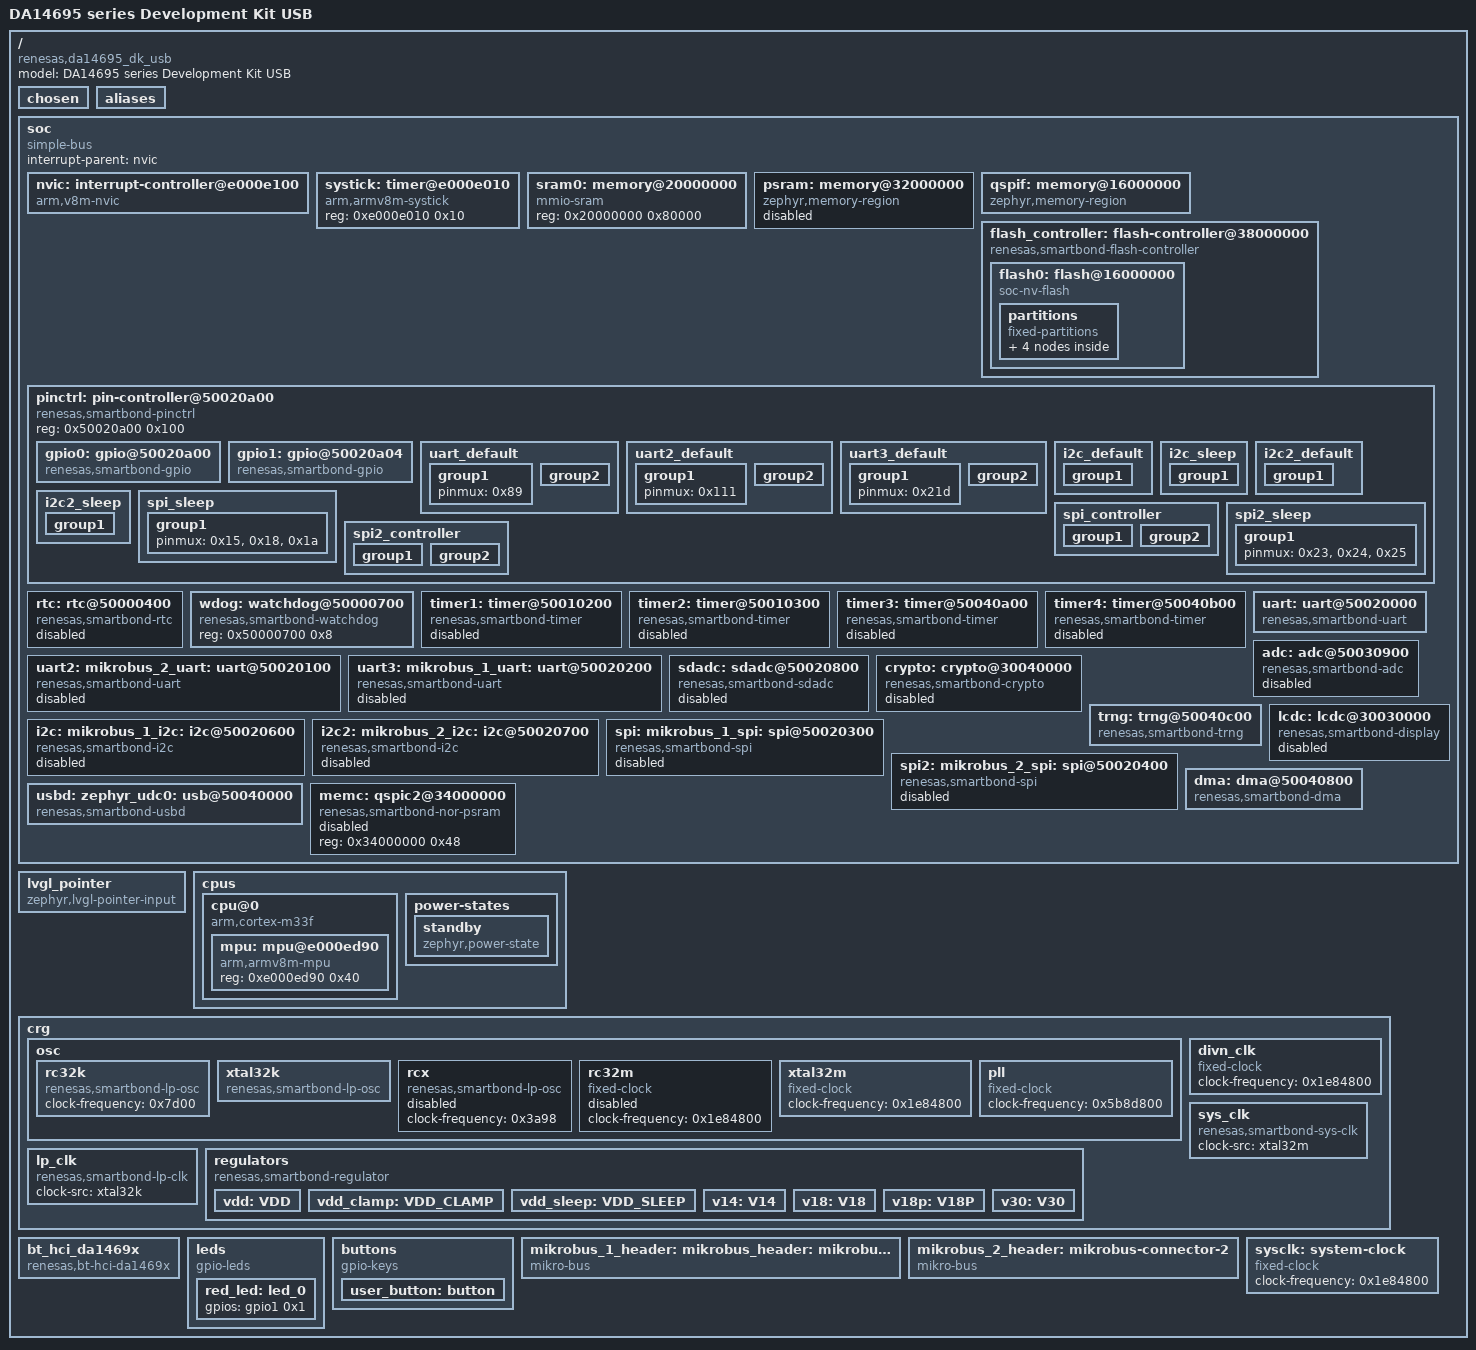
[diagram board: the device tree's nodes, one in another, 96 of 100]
/dts-v1/;

/* node '/' defined in zephyr/dts/common/skeleton.dtsi:9 */
/ {
	model = "DA14695 series Development Kit USB"; /* in zephyr/boards/renesas/da14695_dk_usb/da14695_dk_usb.dts:12 */
	compatible = "renesas,da14695_dk_usb";        /* in zephyr/boards/renesas/da14695_dk_usb/da14695_dk_usb.dts:13 */
	#address-cells = < 0x1 >;                     /* in zephyr/boards/renesas/da14695_dk_usb/da14695_dk_usb.dts:14 */
	#size-cells = < 0x1 >;                        /* in zephyr/boards/renesas/da14695_dk_usb/da14695_dk_usb.dts:15 */

	/* node '/chosen' defined in zephyr/dts/common/skeleton.dtsi:13 */
	chosen {
		zephyr,entropy = &trng;                      /* in zephyr/dts/arm/renesas/smartbond/da1469x.dtsi:16 */
		zephyr,flash-controller = &flash_controller; /* in zephyr/dts/arm/renesas/smartbond/da1469x.dtsi:17 */
		zephyr,sram = &sram0;                        /* in zephyr/boards/renesas/da14695_dk_usb/da14695_dk_usb.dts:18 */
		zephyr,flash = &flash0;                      /* in zephyr/boards/renesas/da14695_dk_usb/da14695_dk_usb.dts:19 */
		zephyr,console = &uart;                      /* in zephyr/boards/renesas/da14695_dk_usb/da14695_dk_usb.dts:20 */
		zephyr,shell-uart = &uart;                   /* in zephyr/boards/renesas/da14695_dk_usb/da14695_dk_usb.dts:21 */
		zephyr,code-partition = &slot0_partition;    /* in zephyr/boards/renesas/da14695_dk_usb/da14695_dk_usb.dts:22 */
		zephyr,bt-hci = &bt_hci_da1469x;             /* in zephyr/boards/renesas/da14695_dk_usb/da14695_dk_usb.dts:23 */
	};

	/* node '/aliases' defined in zephyr/dts/common/skeleton.dtsi:15 */
	aliases {
		led0 = &red_led;    /* in zephyr/boards/renesas/da14695_dk_usb/da14695_dk_usb.dts:91 */
		watchdog0 = &wdog;  /* in zephyr/boards/renesas/da14695_dk_usb/da14695_dk_usb.dts:92 */
		sw0 = &user_button; /* in zephyr/boards/renesas/da14695_dk_usb/da14695_dk_usb.dts:93 */
		rtc = &rtc;         /* in zephyr/boards/renesas/da14695_dk_usb/da14695_dk_usb.dts:94 */
	};

	/* node '/soc' defined in zephyr/dts/arm/armv8-m.dtsi:6 */
	soc {
		#address-cells = < 0x1 >;     /* in zephyr/dts/arm/armv8-m.dtsi:7 */
		#size-cells = < 0x1 >;        /* in zephyr/dts/arm/armv8-m.dtsi:8 */
		compatible = "simple-bus";    /* in zephyr/dts/arm/armv8-m.dtsi:9 */
		interrupt-parent = < &nvic >; /* in zephyr/dts/arm/armv8-m.dtsi:10 */
		ranges;                       /* in zephyr/dts/arm/armv8-m.dtsi:11 */

		/* node '/soc/interrupt-controller@e000e100' defined in zephyr/dts/arm/armv8-m.dtsi:13 */
		nvic: interrupt-controller@e000e100 {
			#address-cells = < 0x1 >;            /* in zephyr/dts/arm/armv8-m.dtsi:14 */
			compatible = "arm,v8m-nvic";         /* in zephyr/dts/arm/armv8-m.dtsi:15 */
			reg = < 0xe000e100 0xc00 >;          /* in zephyr/dts/arm/armv8-m.dtsi:16 */
			interrupt-controller;                /* in zephyr/dts/arm/armv8-m.dtsi:17 */
			#interrupt-cells = < 0x2 >;          /* in zephyr/dts/arm/armv8-m.dtsi:18 */
			arm,num-irq-priority-bits = < 0x4 >; /* in zephyr/dts/arm/renesas/smartbond/da1469x.dtsi:437 */
			phandle = < 0x1 >;                   /* in zephyr/dts/arm/armv8-m.dtsi:10 */
		};

		/* node '/soc/timer@e000e010' defined in zephyr/dts/arm/armv8-m.dtsi:21 */
		systick: timer@e000e010 {
			compatible = "arm,armv8m-systick"; /* in zephyr/dts/arm/armv8-m.dtsi:22 */
			reg = < 0xe000e010 0x10 >;         /* in zephyr/dts/arm/armv8-m.dtsi:23 */
		};

		/* node '/soc/memory@20000000' defined in zephyr/dts/arm/renesas/smartbond/da1469x.dtsi:174 */
		sram0: memory@20000000 {
			compatible = "mmio-sram";     /* in zephyr/dts/arm/renesas/smartbond/da1469x.dtsi:175 */
			reg = < 0x20000000 0x80000 >; /* in zephyr/dts/arm/renesas/smartbond/da14695.dtsi:7 */
		};

		/* node '/soc/memory@32000000' defined in zephyr/dts/arm/renesas/smartbond/da1469x.dtsi:178 */
		psram: memory@32000000 {
			compatible = "zephyr,memory-region"; /* in zephyr/dts/arm/renesas/smartbond/da1469x.dtsi:179 */
			device_type = "memory";              /* in zephyr/dts/arm/renesas/smartbond/da1469x.dtsi:180 */
			reg = < 0x32000000 0x2000000 >;      /* in zephyr/dts/arm/renesas/smartbond/da1469x.dtsi:181 */
			zephyr,memory-region = "PSRAM";      /* in zephyr/dts/arm/renesas/smartbond/da1469x.dtsi:182 */
			status = "disabled";                 /* in zephyr/dts/arm/renesas/smartbond/da1469x.dtsi:183 */
		};

		/* node '/soc/memory@16000000' defined in zephyr/dts/arm/renesas/smartbond/da1469x.dtsi:186 */
		qspif: memory@16000000 {
			compatible = "zephyr,memory-region"; /* in zephyr/dts/arm/renesas/smartbond/da1469x.dtsi:187 */
			reg = < 0x16000000 0x2000000 >;      /* in zephyr/dts/arm/renesas/smartbond/da1469x.dtsi:188 */
			zephyr,memory-region = "QSPIF";      /* in zephyr/dts/arm/renesas/smartbond/da1469x.dtsi:189 */
		};

		/* node '/soc/flash-controller@38000000' defined in zephyr/dts/arm/renesas/smartbond/da1469x.dtsi:192 */
		flash_controller: flash-controller@38000000 {
			compatible = "renesas,smartbond-flash-controller"; /* in zephyr/dts/arm/renesas/smartbond/da1469x.dtsi:193 */
			reg = < 0x38000000 0xb0 >;                         /* in zephyr/dts/arm/renesas/smartbond/da1469x.dtsi:194 */
			#address-cells = < 0x1 >;                          /* in zephyr/dts/arm/renesas/smartbond/da1469x.dtsi:196 */
			#size-cells = < 0x1 >;                             /* in zephyr/dts/arm/renesas/smartbond/da1469x.dtsi:197 */
			read-cs-idle-delay = < 0x32 >;                     /* in zephyr/dts/arm/renesas/smartbond/da1469x.dtsi:199 */
			erase-cs-idle-delay = < 0x32 >;                    /* in zephyr/dts/arm/renesas/smartbond/da1469x.dtsi:200 */

			/* node '/soc/flash-controller@38000000/flash@16000000' defined in zephyr/dts/arm/renesas/smartbond/da1469x.dtsi:202 */
			flash0: flash@16000000 {
				compatible = "soc-nv-flash";   /* in zephyr/dts/arm/renesas/smartbond/da1469x.dtsi:203 */
				erase-block-size = < 0x1000 >; /* in zephyr/dts/arm/renesas/smartbond/da1469x.dtsi:204 */
				write-block-size = < 0x1 >;    /* in zephyr/dts/arm/renesas/smartbond/da1469x.dtsi:205 */
				reg = < 0x16000000 0x400000 >; /* in zephyr/boards/renesas/da14695_dk_usb/da14695_dk_usb.dts:105 */

				/* node '/soc/flash-controller@38000000/flash@16000000/partitions' defined in zephyr/boards/renesas/da14695_dk_usb/da14695_dk_usb.dts:107 */
				partitions {
					compatible = "fixed-partitions"; /* in zephyr/boards/renesas/da14695_dk_usb/da14695_dk_usb.dts:108 */
					#address-cells = < 0x1 >;        /* in zephyr/boards/renesas/da14695_dk_usb/da14695_dk_usb.dts:109 */
					#size-cells = < 0x1 >;           /* in zephyr/boards/renesas/da14695_dk_usb/da14695_dk_usb.dts:110 */

					/* node '/soc/flash-controller@38000000/flash@16000000/partitions/partition@2400' defined in zephyr/boards/renesas/da14695_dk_usb/da14695_dk_usb.dts:125 */
					boot_partition: partition@2400 {
						label = "mcuboot";       /* in zephyr/boards/renesas/da14695_dk_usb/da14695_dk_usb.dts:126 */
						reg = < 0x2400 0xdc00 >; /* in zephyr/boards/renesas/da14695_dk_usb/da14695_dk_usb.dts:127 */
					};

					/* node '/soc/flash-controller@38000000/flash@16000000/partitions/partition@10000' defined in zephyr/boards/renesas/da14695_dk_usb/da14695_dk_usb.dts:129 */
					slot0_partition: partition@10000 {
						label = "image-0";         /* in zephyr/boards/renesas/da14695_dk_usb/da14695_dk_usb.dts:130 */
						reg = < 0x10000 0x80000 >; /* in zephyr/boards/renesas/da14695_dk_usb/da14695_dk_usb.dts:131 */
					};

					/* node '/soc/flash-controller@38000000/flash@16000000/partitions/partition@90000' defined in zephyr/boards/renesas/da14695_dk_usb/da14695_dk_usb.dts:133 */
					slot1_partition: partition@90000 {
						label = "image-1";         /* in zephyr/boards/renesas/da14695_dk_usb/da14695_dk_usb.dts:134 */
						reg = < 0x90000 0x80000 >; /* in zephyr/boards/renesas/da14695_dk_usb/da14695_dk_usb.dts:135 */
					};

					/* node '/soc/flash-controller@38000000/flash@16000000/partitions/partition@110000' defined in zephyr/boards/renesas/da14695_dk_usb/da14695_dk_usb.dts:137 */
					storage_partition: partition@110000 {
						label = "storage";         /* in zephyr/boards/renesas/da14695_dk_usb/da14695_dk_usb.dts:138 */
						reg = < 0x110000 0x8000 >; /* in zephyr/boards/renesas/da14695_dk_usb/da14695_dk_usb.dts:139 */
					};
				};
			};
		};

		/* node '/soc/pin-controller@50020a00' defined in zephyr/dts/arm/renesas/smartbond/da1469x.dtsi:209 */
		pinctrl: pin-controller@50020a00 {
			compatible = "renesas,smartbond-pinctrl"; /* in zephyr/dts/arm/renesas/smartbond/da1469x.dtsi:210 */
			reg = < 0x50020a00 0x100 >;               /* in zephyr/dts/arm/renesas/smartbond/da1469x.dtsi:211 */
			#address-cells = < 0x1 >;                 /* in zephyr/dts/arm/renesas/smartbond/da1469x.dtsi:212 */
			#size-cells = < 0x1 >;                    /* in zephyr/dts/arm/renesas/smartbond/da1469x.dtsi:213 */

			/* node '/soc/pin-controller@50020a00/gpio@50020a00' defined in zephyr/dts/arm/renesas/smartbond/da1469x.dtsi:215 */
			gpio0: gpio@50020a00 {
				compatible = "renesas,smartbond-gpio";                                    /* in zephyr/dts/arm/renesas/smartbond/da1469x.dtsi:216 */
				gpio-controller;                                                          /* in zephyr/dts/arm/renesas/smartbond/da1469x.dtsi:217 */
				#gpio-cells = < 0x2 >;                                                    /* in zephyr/dts/arm/renesas/smartbond/da1469x.dtsi:218 */
				port = < 0x0 >;                                                           /* in zephyr/dts/arm/renesas/smartbond/da1469x.dtsi:219 */
				ngpios = < 0x20 >;                                                        /* in zephyr/dts/arm/renesas/smartbond/da1469x.dtsi:220 */
				reg = < 0x50020a00 0x14 0x50020a18 0x80 0x50000070 0xc 0x50000114 0x24 >; /* in zephyr/dts/arm/renesas/smartbond/da1469x.dtsi:221 */
				reg-names = "data",
				            "mode",
				            "latch",
				            "wkup";                                                       /* in zephyr/dts/arm/renesas/smartbond/da1469x.dtsi:225 */
				interrupts = < 0x26 0x0 >;                                                /* in zephyr/dts/arm/renesas/smartbond/da1469x.dtsi:226 */
				status = "okay";                                                          /* in zephyr/boards/renesas/da14695_dk_usb/da14695_dk_usb.dts:145 */
				phandle = < 0x14 >;                                                       /* in zephyr/boards/renesas/da14695_dk_usb/da14695_dk_usb.dts:38 */
			};

			/* node '/soc/pin-controller@50020a00/gpio@50020a04' defined in zephyr/dts/arm/renesas/smartbond/da1469x.dtsi:229 */
			gpio1: gpio@50020a04 {
				compatible = "renesas,smartbond-gpio";                                    /* in zephyr/dts/arm/renesas/smartbond/da1469x.dtsi:230 */
				gpio-controller;                                                          /* in zephyr/dts/arm/renesas/smartbond/da1469x.dtsi:231 */
				#gpio-cells = < 0x2 >;                                                    /* in zephyr/dts/arm/renesas/smartbond/da1469x.dtsi:232 */
				port = < 0x1 >;                                                           /* in zephyr/dts/arm/renesas/smartbond/da1469x.dtsi:233 */
				reg = < 0x50020a04 0x14 0x50020a98 0x5c 0x5000007c 0xc 0x50000118 0x24 >; /* in zephyr/dts/arm/renesas/smartbond/da1469x.dtsi:235 */
				reg-names = "data",
				            "mode",
				            "latch",
				            "wkup";                                                       /* in zephyr/dts/arm/renesas/smartbond/da1469x.dtsi:239 */
				interrupts = < 0x27 0x0 >;                                                /* in zephyr/dts/arm/renesas/smartbond/da1469x.dtsi:240 */
				ngpios = < 0xc >;                                                         /* in zephyr/dts/arm/renesas/smartbond/da14695.dtsi:11 */
				status = "okay";                                                          /* in zephyr/boards/renesas/da14695_dk_usb/da14695_dk_usb.dts:149 */
				phandle = < 0x13 >;                                                       /* in zephyr/boards/renesas/da14695_dk_usb/da14695_dk_usb.dts:30 */
			};

			/* node '/soc/pin-controller@50020a00/uart_default' defined in zephyr/boards/renesas/da14695_dk_usb/da14695_dk_usb-pinctrl.dtsi:9 */
			uart_default: uart_default {
				phandle = < 0x4 >; /* in zephyr/boards/renesas/da14695_dk_usb/da14695_dk_usb.dts:155 */

				/* node '/soc/pin-controller@50020a00/uart_default/group1' defined in zephyr/boards/renesas/da14695_dk_usb/da14695_dk_usb-pinctrl.dtsi:10 */
				group1 {
					pinmux = < 0x89 >; /* in zephyr/boards/renesas/da14695_dk_usb/da14695_dk_usb-pinctrl.dtsi:11 */
				};

				/* node '/soc/pin-controller@50020a00/uart_default/group2' defined in zephyr/boards/renesas/da14695_dk_usb/da14695_dk_usb-pinctrl.dtsi:14 */
				group2 {
					pinmux = < 0x48 >; /* in zephyr/boards/renesas/da14695_dk_usb/da14695_dk_usb-pinctrl.dtsi:15 */
					bias-pull-up;      /* in zephyr/boards/renesas/da14695_dk_usb/da14695_dk_usb-pinctrl.dtsi:16 */
				};
			};

			/* node '/soc/pin-controller@50020a00/uart2_default' defined in zephyr/boards/renesas/da14695_dk_usb/da14695_dk_usb-pinctrl.dtsi:20 */
			uart2_default: uart2_default {
				phandle = < 0x5 >; /* in zephyr/boards/renesas/da14695_dk_usb/da14695_dk_usb.dts:161 */

				/* node '/soc/pin-controller@50020a00/uart2_default/group1' defined in zephyr/boards/renesas/da14695_dk_usb/da14695_dk_usb-pinctrl.dtsi:21 */
				group1 {
					pinmux = < 0x111 >; /* in zephyr/boards/renesas/da14695_dk_usb/da14695_dk_usb-pinctrl.dtsi:22 */
				};

				/* node '/soc/pin-controller@50020a00/uart2_default/group2' defined in zephyr/boards/renesas/da14695_dk_usb/da14695_dk_usb-pinctrl.dtsi:25 */
				group2 {
					pinmux = < 0xe8 >; /* in zephyr/boards/renesas/da14695_dk_usb/da14695_dk_usb-pinctrl.dtsi:26 */
					bias-pull-up;      /* in zephyr/boards/renesas/da14695_dk_usb/da14695_dk_usb-pinctrl.dtsi:27 */
				};
			};

			/* node '/soc/pin-controller@50020a00/uart3_default' defined in zephyr/boards/renesas/da14695_dk_usb/da14695_dk_usb-pinctrl.dtsi:31 */
			uart3_default: uart3_default {
				phandle = < 0x6 >; /* in zephyr/boards/renesas/da14695_dk_usb/da14695_dk_usb.dts:167 */

				/* node '/soc/pin-controller@50020a00/uart3_default/group1' defined in zephyr/boards/renesas/da14695_dk_usb/da14695_dk_usb-pinctrl.dtsi:32 */
				group1 {
					pinmux = < 0x21d >; /* in zephyr/boards/renesas/da14695_dk_usb/da14695_dk_usb-pinctrl.dtsi:33 */
				};

				/* node '/soc/pin-controller@50020a00/uart3_default/group2' defined in zephyr/boards/renesas/da14695_dk_usb/da14695_dk_usb-pinctrl.dtsi:36 */
				group2 {
					pinmux = < 0x1dc >; /* in zephyr/boards/renesas/da14695_dk_usb/da14695_dk_usb-pinctrl.dtsi:37 */
					bias-pull-up;       /* in zephyr/boards/renesas/da14695_dk_usb/da14695_dk_usb-pinctrl.dtsi:38 */
				};
			};

			/* node '/soc/pin-controller@50020a00/i2c_default' defined in zephyr/boards/renesas/da14695_dk_usb/da14695_dk_usb-pinctrl.dtsi:42 */
			i2c_default: i2c_default {
				phandle = < 0x7 >; /* in zephyr/boards/renesas/da14695_dk_usb/da14695_dk_usb.dts:209 */

				/* node '/soc/pin-controller@50020a00/i2c_default/group1' defined in zephyr/boards/renesas/da14695_dk_usb/da14695_dk_usb-pinctrl.dtsi:43 */
				group1 {
					pinmux = < 0x59f >,
					         < 0x55e >; /* in zephyr/boards/renesas/da14695_dk_usb/da14695_dk_usb-pinctrl.dtsi:44 */
					bias-pull-up;       /* in zephyr/boards/renesas/da14695_dk_usb/da14695_dk_usb-pinctrl.dtsi:46 */
				};
			};

			/* node '/soc/pin-controller@50020a00/i2c_sleep' defined in zephyr/boards/renesas/da14695_dk_usb/da14695_dk_usb-pinctrl.dtsi:50 */
			i2c_sleep: i2c_sleep {
				phandle = < 0x8 >; /* in zephyr/boards/renesas/da14695_dk_usb/da14695_dk_usb.dts:210 */

				/* node '/soc/pin-controller@50020a00/i2c_sleep/group1' defined in zephyr/boards/renesas/da14695_dk_usb/da14695_dk_usb-pinctrl.dtsi:51 */
				group1 {
					pinmux = < 0x1f >,
					         < 0x1e >; /* in zephyr/boards/renesas/da14695_dk_usb/da14695_dk_usb-pinctrl.dtsi:52 */
					bias-pull-up;      /* in zephyr/boards/renesas/da14695_dk_usb/da14695_dk_usb-pinctrl.dtsi:54 */
				};
			};

			/* node '/soc/pin-controller@50020a00/i2c2_default' defined in zephyr/boards/renesas/da14695_dk_usb/da14695_dk_usb-pinctrl.dtsi:58 */
			i2c2_default: i2c2_default {
				phandle = < 0x9 >; /* in zephyr/boards/renesas/da14695_dk_usb/da14695_dk_usb.dts:215 */

				/* node '/soc/pin-controller@50020a00/i2c2_default/group1' defined in zephyr/boards/renesas/da14695_dk_usb/da14695_dk_usb-pinctrl.dtsi:59 */
				group1 {
					pinmux = < 0x613 >,
					         < 0x5d2 >; /* in zephyr/boards/renesas/da14695_dk_usb/da14695_dk_usb-pinctrl.dtsi:60 */
					bias-pull-up;       /* in zephyr/boards/renesas/da14695_dk_usb/da14695_dk_usb-pinctrl.dtsi:62 */
				};
			};

			/* node '/soc/pin-controller@50020a00/i2c2_sleep' defined in zephyr/boards/renesas/da14695_dk_usb/da14695_dk_usb-pinctrl.dtsi:66 */
			i2c2_sleep: i2c2_sleep {
				phandle = < 0xa >; /* in zephyr/boards/renesas/da14695_dk_usb/da14695_dk_usb.dts:216 */

				/* node '/soc/pin-controller@50020a00/i2c2_sleep/group1' defined in zephyr/boards/renesas/da14695_dk_usb/da14695_dk_usb-pinctrl.dtsi:67 */
				group1 {
					pinmux = < 0x13 >,
					         < 0x12 >; /* in zephyr/boards/renesas/da14695_dk_usb/da14695_dk_usb-pinctrl.dtsi:68 */
					bias-pull-up;      /* in zephyr/boards/renesas/da14695_dk_usb/da14695_dk_usb-pinctrl.dtsi:70 */
				};
			};

			/* node '/soc/pin-controller@50020a00/spi_sleep' defined in zephyr/boards/renesas/da14695_dk_usb/da14695_dk_usb-pinctrl.dtsi:74 */
			spi_sleep: spi_sleep {
				phandle = < 0xc >; /* in zephyr/boards/renesas/da14695_dk_usb/da14695_dk_usb.dts:222 */

				/* node '/soc/pin-controller@50020a00/spi_sleep/group1' defined in zephyr/boards/renesas/da14695_dk_usb/da14695_dk_usb-pinctrl.dtsi:75 */
				group1 {
					pinmux = < 0x15 >,
					         < 0x18 >,
					         < 0x1a >; /* in zephyr/boards/renesas/da14695_dk_usb/da14695_dk_usb-pinctrl.dtsi:76 */
				};
			};

			/* node '/soc/pin-controller@50020a00/spi_controller' defined in zephyr/boards/renesas/da14695_dk_usb/da14695_dk_usb-pinctrl.dtsi:82 */
			spi_controller: spi_controller {
				phandle = < 0xb >; /* in zephyr/boards/renesas/da14695_dk_usb/da14695_dk_usb.dts:221 */

				/* node '/soc/pin-controller@50020a00/spi_controller/group1' defined in zephyr/boards/renesas/da14695_dk_usb/da14695_dk_usb-pinctrl.dtsi:83 */
				group1 {
					pinmux = < 0x3d5 >,
					         < 0x39a >; /* in zephyr/boards/renesas/da14695_dk_usb/da14695_dk_usb-pinctrl.dtsi:84 */
					output-enable;      /* in zephyr/boards/renesas/da14695_dk_usb/da14695_dk_usb-pinctrl.dtsi:86 */
				};

				/* node '/soc/pin-controller@50020a00/spi_controller/group2' defined in zephyr/boards/renesas/da14695_dk_usb/da14695_dk_usb-pinctrl.dtsi:89 */
				group2 {
					pinmux = < 0x358 >; /* in zephyr/boards/renesas/da14695_dk_usb/da14695_dk_usb-pinctrl.dtsi:90 */
					input-enable;       /* in zephyr/boards/renesas/da14695_dk_usb/da14695_dk_usb-pinctrl.dtsi:91 */
				};
			};

			/* node '/soc/pin-controller@50020a00/spi2_sleep' defined in zephyr/boards/renesas/da14695_dk_usb/da14695_dk_usb-pinctrl.dtsi:95 */
			spi2_sleep: spi2_sleep {
				phandle = < 0xe >; /* in zephyr/boards/renesas/da14695_dk_usb/da14695_dk_usb.dts:228 */

				/* node '/soc/pin-controller@50020a00/spi2_sleep/group1' defined in zephyr/boards/renesas/da14695_dk_usb/da14695_dk_usb-pinctrl.dtsi:96 */
				group1 {
					pinmux = < 0x23 >,
					         < 0x24 >,
					         < 0x25 >; /* in zephyr/boards/renesas/da14695_dk_usb/da14695_dk_usb-pinctrl.dtsi:97 */
				};
			};

			/* node '/soc/pin-controller@50020a00/spi2_controller' defined in zephyr/boards/renesas/da14695_dk_usb/da14695_dk_usb-pinctrl.dtsi:103 */
			spi2_controller: spi2_controller {
				phandle = < 0xd >; /* in zephyr/boards/renesas/da14695_dk_usb/da14695_dk_usb.dts:227 */

				/* node '/soc/pin-controller@50020a00/spi2_controller/group1' defined in zephyr/boards/renesas/da14695_dk_usb/da14695_dk_usb-pinctrl.dtsi:104 */
				group1 {
					pinmux = < 0x4e3 >,
					         < 0x4a5 >; /* in zephyr/boards/renesas/da14695_dk_usb/da14695_dk_usb-pinctrl.dtsi:105 */
					output-enable;      /* in zephyr/boards/renesas/da14695_dk_usb/da14695_dk_usb-pinctrl.dtsi:107 */
				};

				/* node '/soc/pin-controller@50020a00/spi2_controller/group2' defined in zephyr/boards/renesas/da14695_dk_usb/da14695_dk_usb-pinctrl.dtsi:110 */
				group2 {
					pinmux = < 0x464 >; /* in zephyr/boards/renesas/da14695_dk_usb/da14695_dk_usb-pinctrl.dtsi:111 */
					input-enable;       /* in zephyr/boards/renesas/da14695_dk_usb/da14695_dk_usb-pinctrl.dtsi:112 */
				};
			};
		};

		/* node '/soc/rtc@50000400' defined in zephyr/dts/arm/renesas/smartbond/da1469x.dtsi:244 */
		rtc: rtc@50000400 {
			compatible = "renesas,smartbond-rtc"; /* in zephyr/dts/arm/renesas/smartbond/da1469x.dtsi:245 */
			reg = < 0x50000400 0x98 >;            /* in zephyr/dts/arm/renesas/smartbond/da1469x.dtsi:246 */
			interrupts = < 0x12 0x0 >;            /* in zephyr/dts/arm/renesas/smartbond/da1469x.dtsi:247 */
			alarms-count = < 0x1 >;               /* in zephyr/dts/arm/renesas/smartbond/da1469x.dtsi:248 */
			status = "disabled";                  /* in zephyr/dts/arm/renesas/smartbond/da1469x.dtsi:249 */
		};

		/* node '/soc/watchdog@50000700' defined in zephyr/dts/arm/renesas/smartbond/da1469x.dtsi:252 */
		wdog: watchdog@50000700 {
			compatible = "renesas,smartbond-watchdog"; /* in zephyr/dts/arm/renesas/smartbond/da1469x.dtsi:253 */
			reg = < 0x50000700 0x8 >;                  /* in zephyr/dts/arm/renesas/smartbond/da1469x.dtsi:254 */
			status = "okay";                           /* in zephyr/dts/arm/renesas/smartbond/da1469x.dtsi:255 */
		};

		/* node '/soc/timer@50010200' defined in zephyr/dts/arm/renesas/smartbond/da1469x.dtsi:258 */
		timer1: timer@50010200 {
			compatible = "renesas,smartbond-timer"; /* in zephyr/dts/arm/renesas/smartbond/da1469x.dtsi:259 */
			reg = < 0x50010200 0x300 >;             /* in zephyr/dts/arm/renesas/smartbond/da1469x.dtsi:260 */
			clock-src = < &lp_clk >;                /* in zephyr/dts/arm/renesas/smartbond/da1469x.dtsi:261 */
			interrupts = < 0x10 0x0 >;              /* in zephyr/dts/arm/renesas/smartbond/da1469x.dtsi:262 */
			prescaler = < 0x1 >;                    /* in zephyr/dts/arm/renesas/smartbond/da1469x.dtsi:263 */
			status = "disabled";                    /* in zephyr/dts/arm/renesas/smartbond/da1469x.dtsi:264 */
		};

		/* node '/soc/timer@50010300' defined in zephyr/dts/arm/renesas/smartbond/da1469x.dtsi:267 */
		timer2: timer@50010300 {
			compatible = "renesas,smartbond-timer"; /* in zephyr/dts/arm/renesas/smartbond/da1469x.dtsi:268 */
			reg = < 0x50010300 0x300 >;             /* in zephyr/dts/arm/renesas/smartbond/da1469x.dtsi:269 */
			clock-src = < &divn_clk >;              /* in zephyr/dts/arm/renesas/smartbond/da1469x.dtsi:270 */
			interrupts = < 0x11 0x0 >;              /* in zephyr/dts/arm/renesas/smartbond/da1469x.dtsi:271 */
			prescaler = < 0x20 >;                   /* in zephyr/dts/arm/renesas/smartbond/da1469x.dtsi:272 */
			status = "reserved";                    /* in zephyr/dts/arm/renesas/smartbond/da1469x.dtsi:273 */
		};

		/* node '/soc/timer@50040a00' defined in zephyr/dts/arm/renesas/smartbond/da1469x.dtsi:276 */
		timer3: timer@50040a00 {
			compatible = "renesas,smartbond-timer"; /* in zephyr/dts/arm/renesas/smartbond/da1469x.dtsi:277 */
			reg = < 0x50040a00 0x300 >;             /* in zephyr/dts/arm/renesas/smartbond/da1469x.dtsi:278 */
			clock-src = < &lp_clk >;                /* in zephyr/dts/arm/renesas/smartbond/da1469x.dtsi:279 */
			interrupts = < 0x22 0x0 >;              /* in zephyr/dts/arm/renesas/smartbond/da1469x.dtsi:280 */
			prescaler = < 0x1f >;                   /* in zephyr/dts/arm/renesas/smartbond/da1469x.dtsi:281 */
			status = "disabled";                    /* in zephyr/dts/arm/renesas/smartbond/da1469x.dtsi:282 */
		};

		/* node '/soc/timer@50040b00' defined in zephyr/dts/arm/renesas/smartbond/da1469x.dtsi:285 */
		timer4: timer@50040b00 {
			compatible = "renesas,smartbond-timer"; /* in zephyr/dts/arm/renesas/smartbond/da1469x.dtsi:286 */
			reg = < 0x50040b00 0x300 >;             /* in zephyr/dts/arm/renesas/smartbond/da1469x.dtsi:287 */
			clock-src = < &divn_clk >;              /* in zephyr/dts/arm/renesas/smartbond/da1469x.dtsi:288 */
			interrupts = < 0x23 0x0 >;              /* in zephyr/dts/arm/renesas/smartbond/da1469x.dtsi:289 */
			prescaler = < 0x20 >;                   /* in zephyr/dts/arm/renesas/smartbond/da1469x.dtsi:290 */
			status = "disabled";                    /* in zephyr/dts/arm/renesas/smartbond/da1469x.dtsi:291 */
		};

		/* node '/soc/uart@50020000' defined in zephyr/dts/arm/renesas/smartbond/da1469x.dtsi:294 */
		uart: uart@50020000 {
			compatible = "renesas,smartbond-uart"; /* in zephyr/dts/arm/renesas/smartbond/da1469x.dtsi:295 */
			reg = < 0x50020000 0x100 >;            /* in zephyr/dts/arm/renesas/smartbond/da1469x.dtsi:296 */
			periph-clock-config = < 0x1 >;         /* in zephyr/dts/arm/renesas/smartbond/da1469x.dtsi:297 */
			interrupts = < 0x5 0x0 >;              /* in zephyr/dts/arm/renesas/smartbond/da1469x.dtsi:298 */
			current-speed = < 0x1c200 >;           /* in zephyr/boards/renesas/da14695_dk_usb/da14695_dk_usb.dts:153 */
			status = "okay";                       /* in zephyr/boards/renesas/da14695_dk_usb/da14695_dk_usb.dts:154 */
			pinctrl-0 = < &uart_default >;         /* in zephyr/boards/renesas/da14695_dk_usb/da14695_dk_usb.dts:155 */
			pinctrl-names = "default";             /* in zephyr/boards/renesas/da14695_dk_usb/da14695_dk_usb.dts:156 */
		};

		/* node '/soc/uart@50020100' defined in zephyr/dts/arm/renesas/smartbond/da1469x.dtsi:302 */
		uart2: mikrobus_2_uart: uart@50020100 {
			compatible = "renesas,smartbond-uart"; /* in zephyr/dts/arm/renesas/smartbond/da1469x.dtsi:303 */
			reg = < 0x50020100 0x100 >;            /* in zephyr/dts/arm/renesas/smartbond/da1469x.dtsi:304 */
			periph-clock-config = < 0x2 >;         /* in zephyr/dts/arm/renesas/smartbond/da1469x.dtsi:305 */
			interrupts = < 0x6 0x0 >;              /* in zephyr/dts/arm/renesas/smartbond/da1469x.dtsi:306 */
			hw-flow-control-supported;             /* in zephyr/dts/arm/renesas/smartbond/da1469x.dtsi:307 */
			status = "disabled";                   /* in zephyr/dts/arm/renesas/smartbond/da1469x.dtsi:308 */
			current-speed = < 0x1c200 >;           /* in zephyr/boards/renesas/da14695_dk_usb/da14695_dk_usb.dts:160 */
			pinctrl-0 = < &uart2_default >;        /* in zephyr/boards/renesas/da14695_dk_usb/da14695_dk_usb.dts:161 */
			pinctrl-names = "default";             /* in zephyr/boards/renesas/da14695_dk_usb/da14695_dk_usb.dts:162 */
		};

		/* node '/soc/uart@50020200' defined in zephyr/dts/arm/renesas/smartbond/da1469x.dtsi:311 */
		uart3: mikrobus_1_uart: mikrobus_serial: uart@50020200 {
			compatible = "renesas,smartbond-uart"; /* in zephyr/dts/arm/renesas/smartbond/da1469x.dtsi:312 */
			reg = < 0x50020200 0x100 >;            /* in zephyr/dts/arm/renesas/smartbond/da1469x.dtsi:313 */
			periph-clock-config = < 0x8 >;         /* in zephyr/dts/arm/renesas/smartbond/da1469x.dtsi:314 */
			interrupts = < 0x7 0x0 >;              /* in zephyr/dts/arm/renesas/smartbond/da1469x.dtsi:315 */
			hw-flow-control-supported;             /* in zephyr/dts/arm/renesas/smartbond/da1469x.dtsi:316 */
			status = "disabled";                   /* in zephyr/dts/arm/renesas/smartbond/da1469x.dtsi:317 */
			current-speed = < 0x1c200 >;           /* in zephyr/boards/renesas/da14695_dk_usb/da14695_dk_usb.dts:166 */
			pinctrl-0 = < &uart3_default >;        /* in zephyr/boards/renesas/da14695_dk_usb/da14695_dk_usb.dts:167 */
			pinctrl-names = "default";             /* in zephyr/boards/renesas/da14695_dk_usb/da14695_dk_usb.dts:168 */
		};

		/* node '/soc/adc@50030900' defined in zephyr/dts/arm/renesas/smartbond/da1469x.dtsi:320 */
		adc: adc@50030900 {
			compatible = "renesas,smartbond-adc"; /* in zephyr/dts/arm/renesas/smartbond/da1469x.dtsi:321 */
			reg = < 0x50030900 0x1c >;            /* in zephyr/dts/arm/renesas/smartbond/da1469x.dtsi:322 */
			interrupts = < 0x1b 0x0 >;            /* in zephyr/dts/arm/renesas/smartbond/da1469x.dtsi:323 */
			status = "disabled";                  /* in zephyr/dts/arm/renesas/smartbond/da1469x.dtsi:324 */
			#io-channel-cells = < 0x1 >;          /* in zephyr/dts/arm/renesas/smartbond/da1469x.dtsi:325 */
		};

		/* node '/soc/sdadc@50020800' defined in zephyr/dts/arm/renesas/smartbond/da1469x.dtsi:328 */
		sdadc: sdadc@50020800 {
			compatible = "renesas,smartbond-sdadc"; /* in zephyr/dts/arm/renesas/smartbond/da1469x.dtsi:329 */
			reg = < 0x50020800 0x1c >;              /* in zephyr/dts/arm/renesas/smartbond/da1469x.dtsi:330 */
			interrupts = < 0x1c 0x0 >;              /* in zephyr/dts/arm/renesas/smartbond/da1469x.dtsi:331 */
			clock-freq = < 0x2 >;                   /* in zephyr/dts/arm/renesas/smartbond/da1469x.dtsi:332 */
			status = "disabled";                    /* in zephyr/dts/arm/renesas/smartbond/da1469x.dtsi:333 */
			#io-channel-cells = < 0x1 >;            /* in zephyr/dts/arm/renesas/smartbond/da1469x.dtsi:334 */
		};

		/* node '/soc/crypto@30040000' defined in zephyr/dts/arm/renesas/smartbond/da1469x.dtsi:337 */
		crypto: crypto@30040000 {
			compatible = "renesas,smartbond-crypto"; /* in zephyr/dts/arm/renesas/smartbond/da1469x.dtsi:338 */
			reg = < 0x30040000 0x200 >;              /* in zephyr/dts/arm/renesas/smartbond/da1469x.dtsi:339 */
			interrupts = < 0x1d 0x0 >;               /* in zephyr/dts/arm/renesas/smartbond/da1469x.dtsi:340 */
			status = "disabled";                     /* in zephyr/dts/arm/renesas/smartbond/da1469x.dtsi:341 */
		};

		/* node '/soc/trng@50040c00' defined in zephyr/dts/arm/renesas/smartbond/da1469x.dtsi:344 */
		trng: trng@50040c00 {
			compatible = "renesas,smartbond-trng"; /* in zephyr/dts/arm/renesas/smartbond/da1469x.dtsi:345 */
			reg = < 0x50040c00 0xc >;              /* in zephyr/dts/arm/renesas/smartbond/da1469x.dtsi:346 */
			interrupts = < 0x18 0x0 >;             /* in zephyr/dts/arm/renesas/smartbond/da1469x.dtsi:347 */
			status = "okay";                       /* in zephyr/dts/arm/renesas/smartbond/da1469x.dtsi:348 */
		};

		/* node '/soc/i2c@50020600' defined in zephyr/dts/arm/renesas/smartbond/da1469x.dtsi:351 */
		i2c: mikrobus_1_i2c: mikrobus_i2c: i2c@50020600 {
			compatible = "renesas,smartbond-i2c"; /* in zephyr/dts/arm/renesas/smartbond/da1469x.dtsi:352 */
			#address-cells = < 0x1 >;             /* in zephyr/dts/arm/renesas/smartbond/da1469x.dtsi:353 */
			#size-cells = < 0x0 >;                /* in zephyr/dts/arm/renesas/smartbond/da1469x.dtsi:354 */
			reg = < 0x50020600 0x100 >;           /* in zephyr/dts/arm/renesas/smartbond/da1469x.dtsi:355 */
			periph-clock-config = < 0x200 >;      /* in zephyr/dts/arm/renesas/smartbond/da1469x.dtsi:356 */
			interrupts = < 0x8 0x0 >;             /* in zephyr/dts/arm/renesas/smartbond/da1469x.dtsi:357 */
			status = "disabled";                  /* in zephyr/dts/arm/renesas/smartbond/da1469x.dtsi:358 */
			pinctrl-0 = < &i2c_default >;         /* in zephyr/boards/renesas/da14695_dk_usb/da14695_dk_usb.dts:209 */
			pinctrl-1 = < &i2c_sleep >;           /* in zephyr/boards/renesas/da14695_dk_usb/da14695_dk_usb.dts:210 */
			pinctrl-names = "default",
			                "sleep";              /* in zephyr/boards/renesas/da14695_dk_usb/da14695_dk_usb.dts:211 */
		};

		/* node '/soc/i2c@50020700' defined in zephyr/dts/arm/renesas/smartbond/da1469x.dtsi:361 */
		i2c2: mikrobus_2_i2c: i2c@50020700 {
			compatible = "renesas,smartbond-i2c"; /* in zephyr/dts/arm/renesas/smartbond/da1469x.dtsi:362 */
			#address-cells = < 0x1 >;             /* in zephyr/dts/arm/renesas/smartbond/da1469x.dtsi:363 */
			#size-cells = < 0x0 >;                /* in zephyr/dts/arm/renesas/smartbond/da1469x.dtsi:364 */
			reg = < 0x50020700 0x100 >;           /* in zephyr/dts/arm/renesas/smartbond/da1469x.dtsi:365 */
			periph-clock-config = < 0x800 >;      /* in zephyr/dts/arm/renesas/smartbond/da1469x.dtsi:366 */
			interrupts = < 0x9 0x0 >;             /* in zephyr/dts/arm/renesas/smartbond/da1469x.dtsi:367 */
			status = "disabled";                  /* in zephyr/dts/arm/renesas/smartbond/da1469x.dtsi:368 */
			pinctrl-0 = < &i2c2_default >;        /* in zephyr/boards/renesas/da14695_dk_usb/da14695_dk_usb.dts:215 */
			pinctrl-1 = < &i2c2_sleep >;          /* in zephyr/boards/renesas/da14695_dk_usb/da14695_dk_usb.dts:216 */
			pinctrl-names = "default",
			                "sleep";              /* in zephyr/boards/renesas/da14695_dk_usb/da14695_dk_usb.dts:217 */
		};

		/* node '/soc/lcdc@30030000' defined in zephyr/dts/arm/renesas/smartbond/da1469x.dtsi:371 */
		lcdc: lcdc@30030000 {
			compatible = "renesas,smartbond-display"; /* in zephyr/dts/arm/renesas/smartbond/da1469x.dtsi:372 */
			reg = < 0x30030000 0x18c >;               /* in zephyr/dts/arm/renesas/smartbond/da1469x.dtsi:373 */
			interrupts = < 0x20 0x0 >;                /* in zephyr/dts/arm/renesas/smartbond/da1469x.dtsi:374 */
			status = "disabled";                      /* in zephyr/dts/arm/renesas/smartbond/da1469x.dtsi:375 */
		};

		/* node '/soc/spi@50020300' defined in zephyr/dts/arm/renesas/smartbond/da1469x.dtsi:378 */
		spi: mikrobus_1_spi: mikrobus_spi: spi@50020300 {
			compatible = "renesas,smartbond-spi"; /* in zephyr/dts/arm/renesas/smartbond/da1469x.dtsi:379 */
			#address-cells = < 0x1 >;             /* in zephyr/dts/arm/renesas/smartbond/da1469x.dtsi:380 */
			#size-cells = < 0x0 >;                /* in zephyr/dts/arm/renesas/smartbond/da1469x.dtsi:381 */
			reg = < 0x50020300 0x100 >;           /* in zephyr/dts/arm/renesas/smartbond/da1469x.dtsi:382 */
			periph-clock-config = < 0x20 >;       /* in zephyr/dts/arm/renesas/smartbond/da1469x.dtsi:383 */
			interrupts = < 0xa 0x0 >;             /* in zephyr/dts/arm/renesas/smartbond/da1469x.dtsi:384 */
			status = "disabled";                  /* in zephyr/dts/arm/renesas/smartbond/da1469x.dtsi:385 */
			pinctrl-0 = < &spi_controller >;      /* in zephyr/boards/renesas/da14695_dk_usb/da14695_dk_usb.dts:221 */
			pinctrl-1 = < &spi_sleep >;           /* in zephyr/boards/renesas/da14695_dk_usb/da14695_dk_usb.dts:222 */
			pinctrl-names = "default",
			                "sleep";              /* in zephyr/boards/renesas/da14695_dk_usb/da14695_dk_usb.dts:223 */
		};

		/* node '/soc/spi@50020400' defined in zephyr/dts/arm/renesas/smartbond/da1469x.dtsi:388 */
		spi2: mikrobus_2_spi: spi@50020400 {
			compatible = "renesas,smartbond-spi"; /* in zephyr/dts/arm/renesas/smartbond/da1469x.dtsi:389 */
			#address-cells = < 0x1 >;             /* in zephyr/dts/arm/renesas/smartbond/da1469x.dtsi:390 */
			#size-cells = < 0x0 >;                /* in zephyr/dts/arm/renesas/smartbond/da1469x.dtsi:391 */
			reg = < 0x50020400 0x100 >;           /* in zephyr/dts/arm/renesas/smartbond/da1469x.dtsi:392 */
			periph-clock-config = < 0x80 >;       /* in zephyr/dts/arm/renesas/smartbond/da1469x.dtsi:393 */
			interrupts = < 0xb 0x0 >;             /* in zephyr/dts/arm/renesas/smartbond/da1469x.dtsi:394 */
			status = "disabled";                  /* in zephyr/dts/arm/renesas/smartbond/da1469x.dtsi:395 */
			pinctrl-0 = < &spi2_controller >;     /* in zephyr/boards/renesas/da14695_dk_usb/da14695_dk_usb.dts:227 */
			pinctrl-1 = < &spi2_sleep >;          /* in zephyr/boards/renesas/da14695_dk_usb/da14695_dk_usb.dts:228 */
			pinctrl-names = "default",
			                "sleep";              /* in zephyr/boards/renesas/da14695_dk_usb/da14695_dk_usb.dts:229 */
		};

		/* node '/soc/usb@50040000' defined in zephyr/dts/arm/renesas/smartbond/da1469x.dtsi:398 */
		usbd: zephyr_udc0: usb@50040000 {
			reg = < 0x50040000 0x1b0 >;               /* in zephyr/dts/arm/renesas/smartbond/da1469x.dtsi:400 */
			dmas = < &dma 0x0 0x6 >,
			       < &dma 0x1 0x6 >;                  /* in zephyr/dts/arm/renesas/smartbond/da1469x.dtsi:401 */
			dma-names = "rx",
			            "tx";                         /* in zephyr/dts/arm/renesas/smartbond/da1469x.dtsi:403 */
			dma-min-transfer-size = < 0x41 >;         /* in zephyr/dts/arm/renesas/smartbond/da1469x.dtsi:404 */
			fifo-read-threshold = < 0x4 >;            /* in zephyr/dts/arm/renesas/smartbond/da1469x.dtsi:405 */
			ep-out-buf-size = < 0x8 0x40 0x40 0x40 >; /* in zephyr/dts/arm/renesas/smartbond/da1469x.dtsi:406 */
			interrupts = < 0xf 0x0 >,
			             < 0x15 0x0 >;                /* in zephyr/dts/arm/renesas/smartbond/da1469x.dtsi:407 */
			maximum-speed = "full-speed";             /* in zephyr/dts/arm/renesas/smartbond/da1469x.dtsi:408 */
			num-bidir-endpoints = < 0x4 >;            /* in zephyr/dts/arm/renesas/smartbond/da1469x.dtsi:409 */
			compatible = "renesas,smartbond-usbd";    /* in zephyr/boards/renesas/da14695_dk_usb/da14695_dk_usb.dts:172 */
			status = "okay";                          /* in zephyr/boards/renesas/da14695_dk_usb/da14695_dk_usb.dts:173 */
		};

		/* node '/soc/dma@50040800' defined in zephyr/dts/arm/renesas/smartbond/da1469x.dtsi:413 */
		dma: dma@50040800 {
			compatible = "renesas,smartbond-dma"; /* in zephyr/dts/arm/renesas/smartbond/da1469x.dtsi:414 */
			reg = < 0x50040800 0x110 >;           /* in zephyr/dts/arm/renesas/smartbond/da1469x.dtsi:415 */
			interrupts = < 0x1 0x0 >;             /* in zephyr/dts/arm/renesas/smartbond/da1469x.dtsi:416 */
			status = "okay";                      /* in zephyr/dts/arm/renesas/smartbond/da1469x.dtsi:417 */
			dma-channels = < 0x8 >;               /* in zephyr/dts/arm/renesas/smartbond/da1469x.dtsi:418 */
			block-count = < 0x1 >;                /* in zephyr/dts/arm/renesas/smartbond/da1469x.dtsi:419 */
			#dma-cells = < 0x2 >;                 /* in zephyr/dts/arm/renesas/smartbond/da1469x.dtsi:420 */
			phandle = < 0xf >;                    /* in zephyr/dts/arm/renesas/smartbond/da1469x.dtsi:401 */
		};

		/* node '/soc/qspic2@34000000' defined in zephyr/dts/arm/renesas/smartbond/da1469x.dtsi:423 */
		memc: qspic2@34000000 {
			compatible = "renesas,smartbond-nor-psram"; /* in zephyr/dts/arm/renesas/smartbond/da1469x.dtsi:424 */
			reg = < 0x34000000 0x48 >;                  /* in zephyr/dts/arm/renesas/smartbond/da1469x.dtsi:425 */
			status = "disabled";                        /* in zephyr/dts/arm/renesas/smartbond/da1469x.dtsi:426 */
		};
	};

	/* node '/lvgl_pointer' defined in zephyr/dts/arm/renesas/smartbond/da1469x.dtsi:20 */
	lvgl_pointer {
		compatible = "zephyr,lvgl-pointer-input"; /* in zephyr/dts/arm/renesas/smartbond/da1469x.dtsi:21 */
	};

	/* node '/cpus' defined in zephyr/dts/arm/renesas/smartbond/da1469x.dtsi:24 */
	cpus: cpus {
		#address-cells = < 0x1 >; /* in zephyr/dts/arm/renesas/smartbond/da1469x.dtsi:25 */
		#size-cells = < 0x0 >;    /* in zephyr/dts/arm/renesas/smartbond/da1469x.dtsi:26 */

		/* node '/cpus/cpu@0' defined in zephyr/dts/arm/renesas/smartbond/da1469x.dtsi:28 */
		cpu@0 {
			compatible = "arm,cortex-m33f";  /* in zephyr/dts/arm/renesas/smartbond/da1469x.dtsi:29 */
			reg = < 0x0 >;                   /* in zephyr/dts/arm/renesas/smartbond/da1469x.dtsi:30 */
			clock-frequency = < 0x1e84800 >; /* in zephyr/dts/arm/renesas/smartbond/da1469x.dtsi:31 */
			cpu-power-states = < &standby >; /* in zephyr/dts/arm/renesas/smartbond/da1469x.dtsi:32 */
			#address-cells = < 0x1 >;        /* in zephyr/dts/arm/renesas/smartbond/da1469x.dtsi:34 */
			#size-cells = < 0x1 >;           /* in zephyr/dts/arm/renesas/smartbond/da1469x.dtsi:35 */

			/* node '/cpus/cpu@0/mpu@e000ed90' defined in zephyr/dts/arm/renesas/smartbond/da1469x.dtsi:37 */
			mpu: mpu@e000ed90 {
				compatible = "arm,armv8m-mpu"; /* in zephyr/dts/arm/renesas/smartbond/da1469x.dtsi:38 */
				reg = < 0xe000ed90 0x40 >;     /* in zephyr/dts/arm/renesas/smartbond/da1469x.dtsi:39 */
			};
		};

		/* node '/cpus/power-states' defined in zephyr/dts/arm/renesas/smartbond/da1469x.dtsi:43 */
		power-states {

			/* node '/cpus/power-states/standby' defined in zephyr/dts/arm/renesas/smartbond/da1469x.dtsi:44 */
			standby: standby {
				compatible = "zephyr,power-state"; /* in zephyr/dts/arm/renesas/smartbond/da1469x.dtsi:45 */
				power-state-name = "standby";      /* in zephyr/dts/arm/renesas/smartbond/da1469x.dtsi:46 */
				min-residency-us = < 0x1f4 >;      /* in zephyr/dts/arm/renesas/smartbond/da1469x.dtsi:47 */
				exit-latency-us = < 0x64 >;        /* in zephyr/dts/arm/renesas/smartbond/da1469x.dtsi:48 */
				phandle = < 0x10 >;                /* in zephyr/dts/arm/renesas/smartbond/da1469x.dtsi:32 */
			};
		};
	};

	/* node '/crg' defined in zephyr/dts/arm/renesas/smartbond/da1469x.dtsi:53 */
	crg {

		/* node '/crg/osc' defined in zephyr/dts/arm/renesas/smartbond/da1469x.dtsi:54 */
		osc: osc {

			/* node '/crg/osc/rc32k' defined in zephyr/dts/arm/renesas/smartbond/da1469x.dtsi:55 */
			rc32k: rc32k {
				compatible = "renesas,smartbond-lp-osc"; /* in zephyr/dts/arm/renesas/smartbond/da1469x.dtsi:56 */
				clock-frequency = < 0x7d00 >;            /* in zephyr/dts/arm/renesas/smartbond/da1469x.dtsi:57 */
				#clock-cells = < 0x0 >;                  /* in zephyr/dts/arm/renesas/smartbond/da1469x.dtsi:58 */
				status = "okay";                         /* in zephyr/dts/arm/renesas/smartbond/da1469x.dtsi:59 */
			};

			/* node '/crg/osc/xtal32k' defined in zephyr/dts/arm/renesas/smartbond/da1469x.dtsi:62 */
			xtal32k: xtal32k {
				compatible = "renesas,smartbond-lp-osc"; /* in zephyr/dts/arm/renesas/smartbond/da1469x.dtsi:63 */
				clock-frequency = < 0x8000 >;            /* in zephyr/dts/arm/renesas/smartbond/da1469x.dtsi:64 */
				settle-time = < 0x1f40 >;                /* in zephyr/dts/arm/renesas/smartbond/da1469x.dtsi:65 */
				#clock-cells = < 0x0 >;                  /* in zephyr/dts/arm/renesas/smartbond/da1469x.dtsi:66 */
				status = "okay";                         /* in zephyr/boards/renesas/da14695_dk_usb/da14695_dk_usb.dts:185 */
				phandle = < 0x12 >;                      /* in zephyr/boards/renesas/da14695_dk_usb/da14695_dk_usb.dts:197 */
			};

			/* node '/crg/osc/rcx' defined in zephyr/dts/arm/renesas/smartbond/da1469x.dtsi:70 */
			rcx: rcx {
				compatible = "renesas,smartbond-lp-osc"; /* in zephyr/dts/arm/renesas/smartbond/da1469x.dtsi:71 */
				clock-frequency = < 0x3a98 >;            /* in zephyr/dts/arm/renesas/smartbond/da1469x.dtsi:72 */
				#clock-cells = < 0x0 >;                  /* in zephyr/dts/arm/renesas/smartbond/da1469x.dtsi:73 */
				status = "disabled";                     /* in zephyr/boards/renesas/da14695_dk_usb/da14695_dk_usb.dts:193 */
			};

			/* node '/crg/osc/rc32m' defined in zephyr/dts/arm/renesas/smartbond/da1469x.dtsi:77 */
			rc32m: rc32m {
				compatible = "fixed-clock";      /* in zephyr/dts/arm/renesas/smartbond/da1469x.dtsi:78 */
				clock-frequency = < 0x1e84800 >; /* in zephyr/dts/arm/renesas/smartbond/da1469x.dtsi:79 */
				#clock-cells = < 0x0 >;          /* in zephyr/dts/arm/renesas/smartbond/da1469x.dtsi:80 */
				status = "disabled";             /* in zephyr/boards/renesas/da14695_dk_usb/da14695_dk_usb.dts:177 */
			};

			/* node '/crg/osc/xtal32m' defined in zephyr/dts/arm/renesas/smartbond/da1469x.dtsi:84 */
			xtal32m: xtal32m {
				compatible = "fixed-clock";      /* in zephyr/dts/arm/renesas/smartbond/da1469x.dtsi:85 */
				clock-frequency = < 0x1e84800 >; /* in zephyr/dts/arm/renesas/smartbond/da1469x.dtsi:86 */
				#clock-cells = < 0x0 >;          /* in zephyr/dts/arm/renesas/smartbond/da1469x.dtsi:87 */
				status = "okay";                 /* in zephyr/boards/renesas/da14695_dk_usb/da14695_dk_usb.dts:181 */
				phandle = < 0x11 >;              /* in zephyr/boards/renesas/da14695_dk_usb/da14695_dk_usb.dts:201 */
			};

			/* node '/crg/osc/pll' defined in zephyr/dts/arm/renesas/smartbond/da1469x.dtsi:91 */
			pll: pll {
				compatible = "fixed-clock";      /* in zephyr/dts/arm/renesas/smartbond/da1469x.dtsi:92 */
				clock-frequency = < 0x5b8d800 >; /* in zephyr/dts/arm/renesas/smartbond/da1469x.dtsi:93 */
				#clock-cells = < 0x0 >;          /* in zephyr/dts/arm/renesas/smartbond/da1469x.dtsi:94 */
				status = "okay";                 /* in zephyr/boards/renesas/da14695_dk_usb/da14695_dk_usb.dts:205 */
			};
		};

		/* node '/crg/divn_clk' defined in zephyr/dts/arm/renesas/smartbond/da1469x.dtsi:99 */
		divn_clk: divn_clk {
			compatible = "fixed-clock";      /* in zephyr/dts/arm/renesas/smartbond/da1469x.dtsi:100 */
			clock-frequency = < 0x1e84800 >; /* in zephyr/dts/arm/renesas/smartbond/da1469x.dtsi:101 */
			#clock-cells = < 0x0 >;          /* in zephyr/dts/arm/renesas/smartbond/da1469x.dtsi:102 */
			status = "okay";                 /* in zephyr/dts/arm/renesas/smartbond/da1469x.dtsi:103 */
			phandle = < 0x3 >;               /* in zephyr/dts/arm/renesas/smartbond/da1469x.dtsi:270 */
		};

		/* node '/crg/sys_clk' defined in zephyr/dts/arm/renesas/smartbond/da1469x.dtsi:106 */
		sys_clk: sys_clk {
			compatible = "renesas,smartbond-sys-clk"; /* in zephyr/dts/arm/renesas/smartbond/da1469x.dtsi:107 */
			status = "okay";                          /* in zephyr/dts/arm/renesas/smartbond/da1469x.dtsi:110 */
			clock-src = < &xtal32m >;                 /* in zephyr/boards/renesas/da14695_dk_usb/da14695_dk_usb.dts:201 */
		};

		/* node '/crg/lp_clk' defined in zephyr/dts/arm/renesas/smartbond/da1469x.dtsi:113 */
		lp_clk: lp_clk {
			compatible = "renesas,smartbond-lp-clk"; /* in zephyr/dts/arm/renesas/smartbond/da1469x.dtsi:114 */
			status = "okay";                         /* in zephyr/dts/arm/renesas/smartbond/da1469x.dtsi:116 */
			clock-src = < &xtal32k >;                /* in zephyr/boards/renesas/da14695_dk_usb/da14695_dk_usb.dts:197 */
			phandle = < 0x2 >;                       /* in zephyr/dts/arm/renesas/smartbond/da1469x.dtsi:261 */
		};

		/* node '/crg/regulators' defined in zephyr/dts/arm/renesas/smartbond/da1469x.dtsi:119 */
		regulators {
			compatible = "renesas,smartbond-regulator"; /* in zephyr/dts/arm/renesas/smartbond/da1469x.dtsi:120 */

			/* node '/crg/regulators/VDD' defined in zephyr/dts/arm/renesas/smartbond/da1469x.dtsi:122 */
			vdd: VDD {
				regulator-init-microvolt = < 0xdbba0 >; /* in zephyr/dts/arm/renesas/smartbond/da1469x.dtsi:123 */
				regulator-boot-on;                      /* in zephyr/dts/arm/renesas/smartbond/da1469x.dtsi:124 */
				renesas,regulator-sleep-ldo;            /* in zephyr/dts/arm/renesas/smartbond/da1469x.dtsi:125 */
				renesas,regulator-dcdc-vbat-high;       /* in zephyr/dts/arm/renesas/smartbond/da1469x.dtsi:126 */
				renesas,regulator-dcdc-vbat-low;        /* in zephyr/dts/arm/renesas/smartbond/da1469x.dtsi:127 */
			};

			/* node '/crg/regulators/VDD_CLAMP' defined in zephyr/dts/arm/renesas/smartbond/da1469x.dtsi:130 */
			vdd_clamp: VDD_CLAMP {
				regulator-boot-on;                      /* in zephyr/dts/arm/renesas/smartbond/da1469x.dtsi:131 */
				regulator-always-on;                    /* in zephyr/dts/arm/renesas/smartbond/da1469x.dtsi:132 */
				regulator-init-microvolt = < 0xac5d0 >; /* in zephyr/dts/arm/renesas/smartbond/da1469x.dtsi:133 */
			};

			/* node '/crg/regulators/VDD_SLEEP' defined in zephyr/dts/arm/renesas/smartbond/da1469x.dtsi:136 */
			vdd_sleep: VDD_SLEEP {
				regulator-boot-on;                      /* in zephyr/dts/arm/renesas/smartbond/da1469x.dtsi:137 */
				regulator-init-microvolt = < 0xb71b0 >; /* in zephyr/dts/arm/renesas/smartbond/da1469x.dtsi:138 */
			};

			/* node '/crg/regulators/V14' defined in zephyr/dts/arm/renesas/smartbond/da1469x.dtsi:141 */
			v14: V14 {
				regulator-init-microvolt = < 0x155cc0 >; /* in zephyr/dts/arm/renesas/smartbond/da1469x.dtsi:142 */
				regulator-boot-on;                       /* in zephyr/dts/arm/renesas/smartbond/da1469x.dtsi:143 */
				renesas,regulator-dcdc-vbat-high;        /* in zephyr/dts/arm/renesas/smartbond/da1469x.dtsi:144 */
				renesas,regulator-dcdc-vbat-low;         /* in zephyr/dts/arm/renesas/smartbond/da1469x.dtsi:145 */
			};

			/* node '/crg/regulators/V18' defined in zephyr/dts/arm/renesas/smartbond/da1469x.dtsi:148 */
			v18: V18 {
				regulator-init-microvolt = < 0x1b7740 >; /* in zephyr/dts/arm/renesas/smartbond/da1469x.dtsi:149 */
				regulator-boot-on;                       /* in zephyr/dts/arm/renesas/smartbond/da1469x.dtsi:150 */
				renesas,regulator-dcdc-vbat-high;        /* in zephyr/dts/arm/renesas/smartbond/da1469x.dtsi:151 */
			};

			/* node '/crg/regulators/V18P' defined in zephyr/dts/arm/renesas/smartbond/da1469x.dtsi:154 */
			v18p: V18P {
				regulator-init-microvolt = < 0x1b7740 >; /* in zephyr/dts/arm/renesas/smartbond/da1469x.dtsi:155 */
				regulator-boot-on;                       /* in zephyr/dts/arm/renesas/smartbond/da1469x.dtsi:156 */
				renesas,regulator-sleep-ldo;             /* in zephyr/dts/arm/renesas/smartbond/da1469x.dtsi:157 */
				renesas,regulator-dcdc-vbat-high;        /* in zephyr/dts/arm/renesas/smartbond/da1469x.dtsi:158 */
			};

			/* node '/crg/regulators/V30' defined in zephyr/dts/arm/renesas/smartbond/da1469x.dtsi:161 */
			v30: V30 {
				regulator-init-microvolt = < 0x2dc6c0 >; /* in zephyr/dts/arm/renesas/smartbond/da1469x.dtsi:162 */
				regulator-boot-on;                       /* in zephyr/dts/arm/renesas/smartbond/da1469x.dtsi:163 */
				renesas,regulator-sleep-ldo;             /* in zephyr/dts/arm/renesas/smartbond/da1469x.dtsi:164 */
				renesas,regulator-v30-vbus;              /* in zephyr/dts/arm/renesas/smartbond/da1469x.dtsi:165 */
				renesas,regulator-v30-vbat;              /* in zephyr/dts/arm/renesas/smartbond/da1469x.dtsi:166 */
				renesas,regulator-v30-clamp;             /* in zephyr/dts/arm/renesas/smartbond/da1469x.dtsi:167 */
				renesas,regulator-v30-ref-bandgap;       /* in zephyr/dts/arm/renesas/smartbond/da1469x.dtsi:168 */
			};
		};
	};

	/* node '/bt_hci_da1469x' defined in zephyr/dts/arm/renesas/smartbond/da1469x.dtsi:430 */
	bt_hci_da1469x: bt_hci_da1469x {
		compatible = "renesas,bt-hci-da1469x"; /* in zephyr/dts/arm/renesas/smartbond/da1469x.dtsi:431 */
		status = "okay";                       /* in zephyr/boards/renesas/da14695_dk_usb/da14695_dk_usb.dts:233 */
	};

	/* node '/leds' defined in zephyr/boards/renesas/da14695_dk_usb/da14695_dk_usb.dts:26 */
	leds {
		compatible = "gpio-leds"; /* in zephyr/boards/renesas/da14695_dk_usb/da14695_dk_usb.dts:27 */

		/* node '/leds/led_0' defined in zephyr/boards/renesas/da14695_dk_usb/da14695_dk_usb.dts:29 */
		red_led: led_0 {
			gpios = < &gpio1 0x1 0x0 >; /* in zephyr/boards/renesas/da14695_dk_usb/da14695_dk_usb.dts:30 */
		};
	};

	/* node '/buttons' defined in zephyr/boards/renesas/da14695_dk_usb/da14695_dk_usb.dts:34 */
	buttons {
		compatible = "gpio-keys"; /* in zephyr/boards/renesas/da14695_dk_usb/da14695_dk_usb.dts:35 */

		/* node '/buttons/button' defined in zephyr/boards/renesas/da14695_dk_usb/da14695_dk_usb.dts:37 */
		user_button: button {
			gpios = < &gpio0 0x6 0x20 >; /* in zephyr/boards/renesas/da14695_dk_usb/da14695_dk_usb.dts:38 */
			label = "User (K1)";         /* in zephyr/boards/renesas/da14695_dk_usb/da14695_dk_usb.dts:39 */
			zephyr,code = < 0xb >;       /* in zephyr/boards/renesas/da14695_dk_usb/da14695_dk_usb.dts:40 */
		};
	};

	/* node '/mikrobus-connector-1' defined in zephyr/boards/renesas/da14695_dk_usb/da14695_dk_usb.dts:44 */
	mikrobus_1_header: mikrobus_header: mikrobus-connector-1 {
		compatible = "mikro-bus";                  /* in zephyr/boards/renesas/da14695_dk_usb/da14695_dk_usb.dts:45 */
		#gpio-cells = < 0x2 >;                     /* in zephyr/boards/renesas/da14695_dk_usb/da14695_dk_usb.dts:46 */
		gpio-map-mask = < 0xffffffff 0xffffffc0 >; /* in zephyr/boards/renesas/da14695_dk_usb/da14695_dk_usb.dts:47 */
		gpio-map-pass-thru = < 0x0 0x3f >;         /* in zephyr/boards/renesas/da14695_dk_usb/da14695_dk_usb.dts:48 */
		gpio-map = < 0x0 0x0 &gpio1 0x9 0x0 >,
		           < 0x1 0x0 &gpio0 0xc 0x0 >,
		           < 0x2 0x0 &gpio0 0x14 0x0 >,
		           < 0x3 0x0 &gpio0 0x15 0x0 >,
		           < 0x4 0x0 &gpio0 0x18 0x0 >,
		           < 0x5 0x0 &gpio0 0x1a 0x0 >,
		           < 0x6 0x0 &gpio1 0x1 0x0 >,
		           < 0x7 0x0 &gpio0 0x1b 0x0 >,
		           < 0x8 0x0 &gpio0 0x1c 0x0 >,
		           < 0x9 0x0 &gpio0 0x1d 0x0 >,
		           < 0xa 0x0 &gpio0 0x1e 0x0 >,
		           < 0xb 0x0 &gpio0 0x1f 0x0 >;    /* in zephyr/boards/renesas/da14695_dk_usb/da14695_dk_usb.dts:49 */
	};

	/* node '/mikrobus-connector-2' defined in zephyr/boards/renesas/da14695_dk_usb/da14695_dk_usb.dts:67 */
	mikrobus_2_header: mikrobus-connector-2 {
		compatible = "mikro-bus";                  /* in zephyr/boards/renesas/da14695_dk_usb/da14695_dk_usb.dts:68 */
		#gpio-cells = < 0x2 >;                     /* in zephyr/boards/renesas/da14695_dk_usb/da14695_dk_usb.dts:69 */
		gpio-map-mask = < 0xffffffff 0xffffffc0 >; /* in zephyr/boards/renesas/da14695_dk_usb/da14695_dk_usb.dts:70 */
		gpio-map-pass-thru = < 0x0 0x3f >;         /* in zephyr/boards/renesas/da14695_dk_usb/da14695_dk_usb.dts:71 */
		gpio-map = < 0x0 0x0 &gpio0 0x19 0x0 >,
		           < 0x1 0x0 &gpio0 0xc 0x0 >,
		           < 0x2 0x0 &gpio1 0x2 0x0 >,
		           < 0x3 0x0 &gpio1 0x3 0x0 >,
		           < 0x4 0x0 &gpio1 0x4 0x0 >,
		           < 0x5 0x0 &gpio1 0x5 0x0 >,
		           < 0x6 0x0 &gpio1 0x6 0x0 >,
		           < 0x7 0x0 &gpio1 0x7 0x0 >,
		           < 0x8 0x0 &gpio1 0x8 0x0 >,
		           < 0x9 0x0 &gpio0 0x11 0x0 >,
		           < 0xa 0x0 &gpio0 0x12 0x0 >,
		           < 0xb 0x0 &gpio0 0x13 0x0 >;    /* in zephyr/boards/renesas/da14695_dk_usb/da14695_dk_usb.dts:72 */
	};

	/* node '/system-clock' defined in zephyr/boards/renesas/da14695_dk_usb/da14695_dk_usb.dts:97 */
	sysclk: system-clock {
		compatible = "fixed-clock";      /* in zephyr/boards/renesas/da14695_dk_usb/da14695_dk_usb.dts:98 */
		clock-frequency = < 0x1e84800 >; /* in zephyr/boards/renesas/da14695_dk_usb/da14695_dk_usb.dts:99 */
		#clock-cells = < 0x0 >;          /* in zephyr/boards/renesas/da14695_dk_usb/da14695_dk_usb.dts:100 */
	};
};
